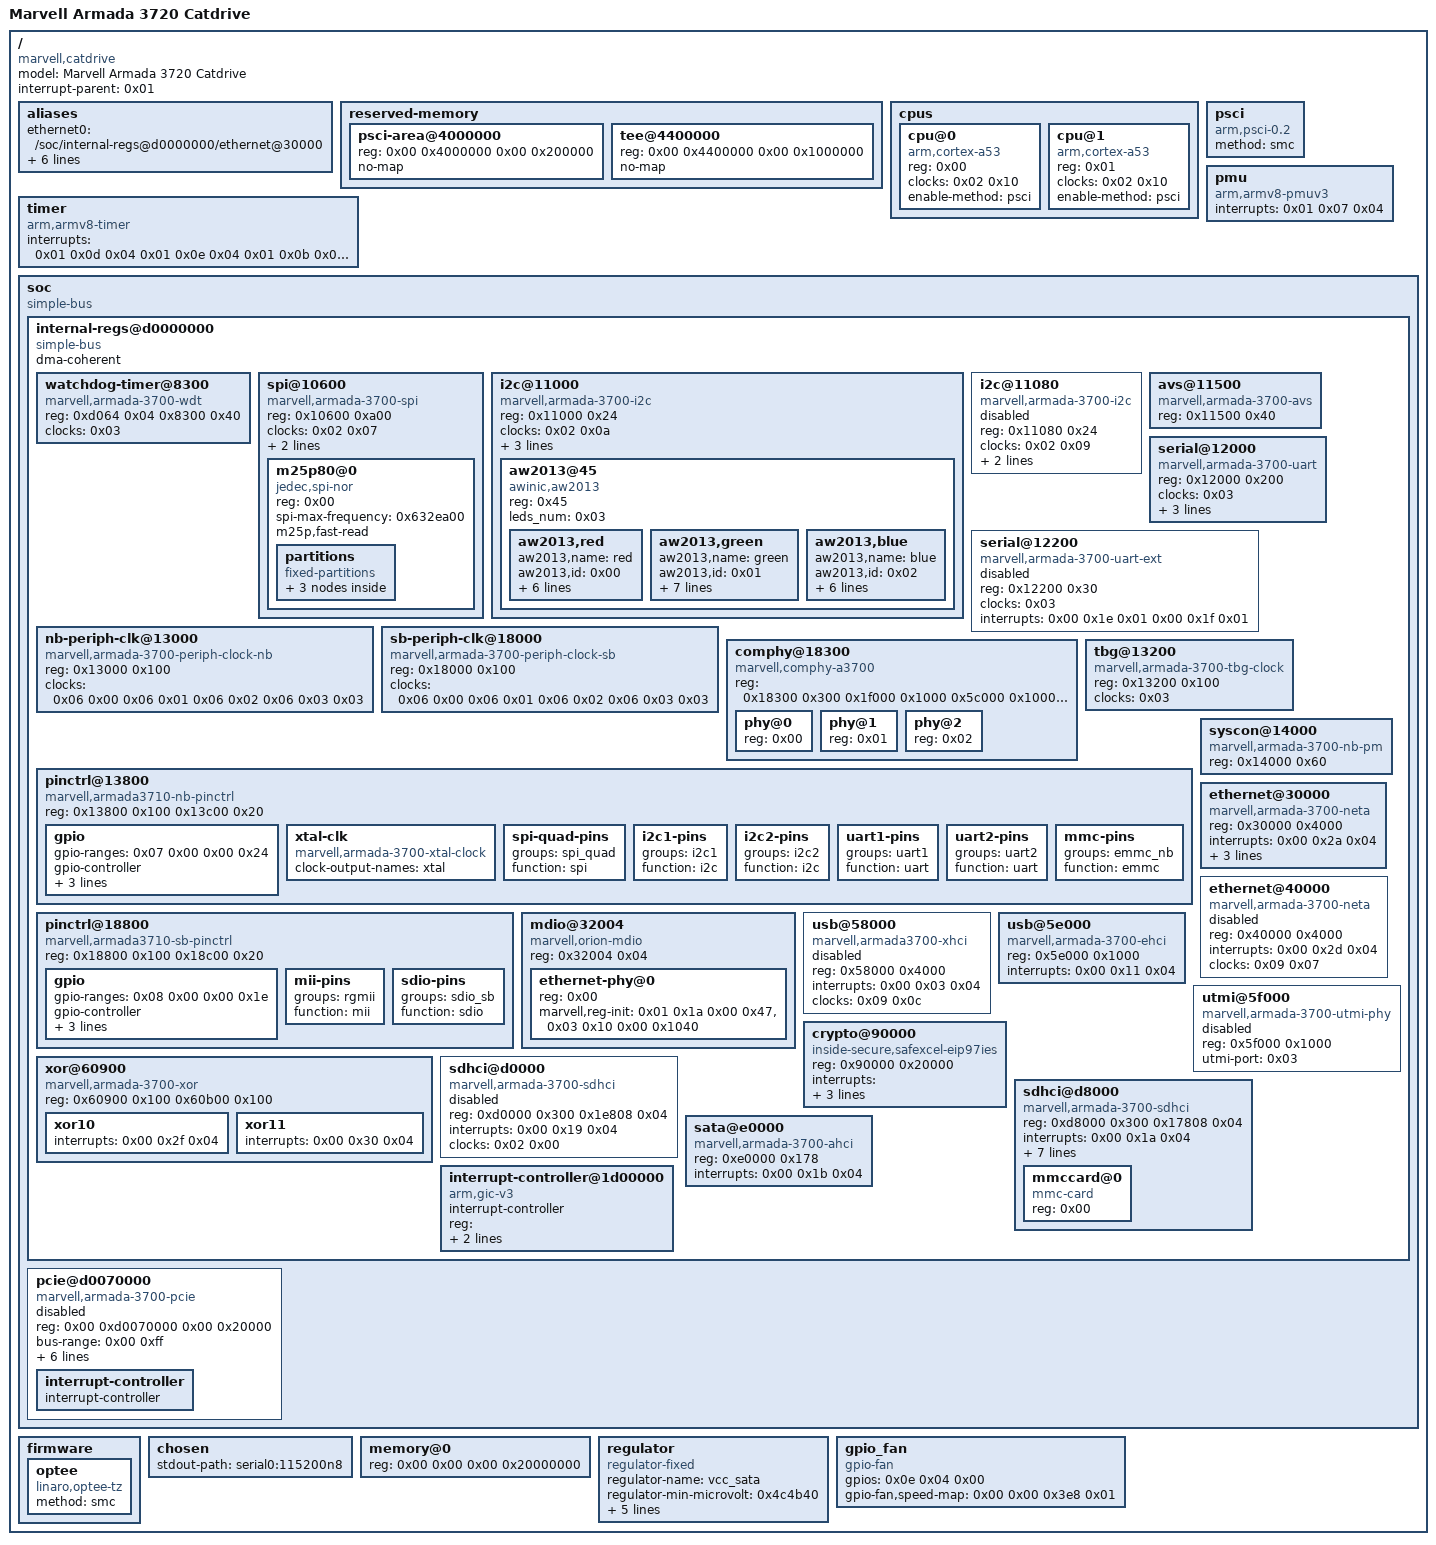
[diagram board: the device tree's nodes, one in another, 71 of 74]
/dts-v1/;

/ {
	model = "Marvell Armada 3720 Catdrive";
	compatible = "marvell,catdrive\0marvell,armada3720\0marvell,armada3710";
	interrupt-parent = <0x01>;
	#address-cells = <0x02>;
	#size-cells = <0x02>;

	aliases {
		ethernet0 = "/soc/internal-regs@d0000000/ethernet@30000";
		ethernet1 = "/soc/internal-regs@d0000000/ethernet@40000";
		serial0 = "/soc/internal-regs@d0000000/serial@12000";
		serial1 = "/soc/internal-regs@d0000000/serial@12200";
	};

	reserved-memory {
		#address-cells = <0x02>;
		#size-cells = <0x02>;
		ranges;

		psci-area@4000000 {
			reg = <0x00 0x4000000 0x00 0x200000>;
			no-map;
		};

		tee@4400000 {
			reg = <0x00 0x4400000 0x00 0x1000000>;
			no-map;
		};
	};

	cpus {
		#address-cells = <0x01>;
		#size-cells = <0x00>;

		cpu@0 {
			device_type = "cpu";
			compatible = "arm,cortex-a53\0arm,armv8";
			reg = <0x00>;
			clocks = <0x02 0x10>;
			enable-method = "psci";
		};

		cpu@1 {
			device_type = "cpu";
			compatible = "arm,cortex-a53\0arm,armv8";
			reg = <0x01>;
			clocks = <0x02 0x10>;
			enable-method = "psci";
		};
	};

	psci {
		compatible = "arm,psci-0.2";
		method = "smc";
	};

	timer {
		compatible = "arm,armv8-timer";
		interrupts = <0x01 0x0d 0x04 0x01 0x0e 0x04 0x01 0x0b 0x04 0x01 0x0a 0x04>;
	};

	pmu {
		compatible = "arm,armv8-pmuv3";
		interrupts = <0x01 0x07 0x04>;
	};

	soc {
		compatible = "simple-bus";
		#address-cells = <0x02>;
		#size-cells = <0x02>;
		ranges;

		internal-regs@d0000000 {
			#address-cells = <0x01>;
			#size-cells = <0x01>;
			compatible = "simple-bus";
			ranges = <0x00 0x00 0xd0000000 0x2000000>;
			dma-coherent;

			watchdog-timer@8300 {
				compatible = "marvell,armada-3700-wdt";
				reg = <0xd064 0x04 0x8300 0x40>;
				clocks = <0x03>;
			};

			spi@10600 {
				compatible = "marvell,armada-3700-spi";
				#address-cells = <0x01>;
				#size-cells = <0x00>;
				reg = <0x10600 0xa00>;
				clocks = <0x02 0x07>;
				interrupts = <0x00 0x00 0x04>;
				num-cs = <0x04>;
				status = "okay";

				m25p80@0 {
					reg = <0x00>;
					compatible = "jedec,spi-nor";
					spi-max-frequency = <0x632ea00>;
					m25p,fast-read;
					status = "okay";

					partitions {
						compatible = "fixed-partitions";
						#address-cells = <0x01>;
						#size-cells = <0x01>;

						partition@0 {
							label = "uboot";
							reg = <0x00 0x1f0000>;
						};

						partition@1f0000 {
							label = "ubootenv";
							reg = <0x1f0000 0x10000>;
						};

						partition@200000 {
							label = "reserve";
							reg = <0x200000 0x600000>;
						};
					};
				};
			};

			i2c@11000 {
				compatible = "marvell,armada-3700-i2c";
				reg = <0x11000 0x24>;
				#address-cells = <0x01>;
				#size-cells = <0x00>;
				clocks = <0x02 0x0a>;
				interrupts = <0x00 0x01 0x04>;
				mrvl,i2c-fast-mode;
				status = "okay";
				pinctrl-names = "default";
				pinctrl-0 = <0x04>;

				aw2013@45 {
					compatible = "awinic,aw2013";
					reg = <0x45>;
					leds_num = <0x03>;

					aw2013,red {
						aw2013,name = "red";
						aw2013,id = <0x00>;
						aw2013,max-brightness = <0xff>;
						aw2013,max-current = <0x03>;
						aw2013,rise-time-ms = <0x02>;
						aw2013,hold-time-ms = <0x01>;
						aw2013,fall-time-ms = <0x02>;
						aw2013,off-time-ms = <0x01>;
					};

					aw2013,green {
						aw2013,name = "green";
						aw2013,id = <0x01>;
						aw2013,max-brightness = <0xff>;
						aw2013,max-current = <0x03>;
						aw2013,rise-time-ms = <0x02>;
						aw2013,hold-time-ms = <0x01>;
						aw2013,fall-time-ms = <0x02>;
						aw2013,off-time-ms = <0x01>;
						default-state = "on";
					};

					aw2013,blue {
						aw2013,name = "blue";
						aw2013,id = <0x02>;
						aw2013,max-brightness = <0xff>;
						aw2013,max-current = <0x03>;
						aw2013,rise-time-ms = <0x02>;
						aw2013,hold-time-ms = <0x01>;
						aw2013,fall-time-ms = <0x02>;
						aw2013,off-time-ms = <0x01>;
					};
				};
			};

			i2c@11080 {
				compatible = "marvell,armada-3700-i2c";
				reg = <0x11080 0x24>;
				#address-cells = <0x01>;
				#size-cells = <0x00>;
				clocks = <0x02 0x09>;
				interrupts = <0x00 0x02 0x04>;
				mrvl,i2c-fast-mode;
				status = "disabled";
			};

			avs@11500 {
				compatible = "marvell,armada-3700-avs\0syscon";
				reg = <0x11500 0x40>;
			};

			serial@12000 {
				compatible = "marvell,armada-3700-uart";
				reg = <0x12000 0x200>;
				clocks = <0x03>;
				interrupts = <0x00 0x0b 0x04 0x00 0x0c 0x04 0x00 0x0d 0x04>;
				interrupt-names = "uart-sum\0uart-tx\0uart-rx";
				status = "okay";
				pinctrl-names = "default";
				pinctrl-0 = <0x05>;
			};

			serial@12200 {
				compatible = "marvell,armada-3700-uart-ext";
				reg = <0x12200 0x30>;
				clocks = <0x03>;
				interrupts = <0x00 0x1e 0x01 0x00 0x1f 0x01>;
				interrupt-names = "uart-tx\0uart-rx";
				status = "disabled";
			};

			nb-periph-clk@13000 {
				compatible = "marvell,armada-3700-periph-clock-nb";
				reg = <0x13000 0x100>;
				clocks = <0x06 0x00 0x06 0x01 0x06 0x02 0x06 0x03 0x03>;
				#clock-cells = <0x01>;
				linux,phandle = <0x02>;
				phandle = <0x02>;
			};

			sb-periph-clk@18000 {
				compatible = "marvell,armada-3700-periph-clock-sb";
				reg = <0x18000 0x100>;
				clocks = <0x06 0x00 0x06 0x01 0x06 0x02 0x06 0x03 0x03>;
				#clock-cells = <0x01>;
				linux,phandle = <0x09>;
				phandle = <0x09>;
			};

			comphy@18300 {
				compatible = "marvell,comphy-a3700";
				reg = <0x18300 0x300 0x1f000 0x1000 0x5c000 0x1000 0xe0178 0x08>;
				reg-names = "comphy\0serdes\0usb3_gbe1_phy\0indirect_ahci";
				#address-cells = <0x01>;
				#size-cells = <0x00>;

				phy@0 {
					reg = <0x00>;
					#phy-cells = <0x01>;
				};

				phy@1 {
					reg = <0x01>;
					#phy-cells = <0x01>;
				};

				phy@2 {
					reg = <0x02>;
					#phy-cells = <0x01>;
				};
			};

			tbg@13200 {
				compatible = "marvell,armada-3700-tbg-clock";
				reg = <0x13200 0x100>;
				clocks = <0x03>;
				#clock-cells = <0x01>;
				linux,phandle = <0x06>;
				phandle = <0x06>;
			};

			pinctrl@13800 {
				compatible = "marvell,armada3710-nb-pinctrl\0syscon\0simple-mfd";
				reg = <0x13800 0x100 0x13c00 0x20>;
				linux,phandle = <0x07>;
				phandle = <0x07>;

				gpio {
					#gpio-cells = <0x02>;
					gpio-ranges = <0x07 0x00 0x00 0x24>;
					gpio-controller;
					interrupt-controller;
					#interrupt-cells = <0x02>;
					interrupts = <0x00 0x33 0x04 0x00 0x34 0x04 0x00 0x35 0x04 0x00 0x36 0x04 0x00 0x37 0x04 0x00 0x38 0x04 0x00 0x39 0x04 0x00 0x3a 0x04 0x00 0x98 0x04 0x00 0x99 0x04 0x00 0x9a 0x04 0x00 0x9b 0x04>;
				};

				xtal-clk {
					compatible = "marvell,armada-3700-xtal-clock";
					clock-output-names = "xtal";
					#clock-cells = <0x00>;
					linux,phandle = <0x03>;
					phandle = <0x03>;
				};

				spi-quad-pins {
					groups = "spi_quad";
					function = "spi";
				};

				i2c1-pins {
					groups = "i2c1";
					function = "i2c";
					linux,phandle = <0x04>;
					phandle = <0x04>;
				};

				i2c2-pins {
					groups = "i2c2";
					function = "i2c";
				};

				uart1-pins {
					groups = "uart1";
					function = "uart";
					linux,phandle = <0x05>;
					phandle = <0x05>;
				};

				uart2-pins {
					groups = "uart2";
					function = "uart";
				};

				mmc-pins {
					groups = "emmc_nb";
					function = "emmc";
					linux,phandle = <0x0b>;
					phandle = <0x0b>;
				};
			};

			syscon@14000 {
				compatible = "marvell,armada-3700-nb-pm\0syscon";
				reg = <0x14000 0x60>;
			};

			pinctrl@18800 {
				compatible = "marvell,armada3710-sb-pinctrl\0syscon\0simple-mfd";
				reg = <0x18800 0x100 0x18c00 0x20>;
				linux,phandle = <0x08>;
				phandle = <0x08>;

				gpio {
					#gpio-cells = <0x02>;
					gpio-ranges = <0x08 0x00 0x00 0x1e>;
					gpio-controller;
					interrupt-controller;
					#interrupt-cells = <0x02>;
					interrupts = <0x00 0xa0 0x04 0x00 0x9f 0x04 0x00 0x9e 0x04 0x00 0x9d 0x04 0x00 0x9c 0x04>;
					linux,phandle = <0x0e>;
					phandle = <0x0e>;
				};

				mii-pins {
					groups = "rgmii";
					function = "mii";
				};

				sdio-pins {
					groups = "sdio_sb";
					function = "sdio";
				};
			};

			ethernet@30000 {
				compatible = "marvell,armada-3700-neta";
				reg = <0x30000 0x4000>;
				interrupts = <0x00 0x2a 0x04>;
				clocks = <0x09 0x08>;
				status = "okay";
				phy-mode = "sgmii";
				phy = <0x0a>;
			};

			mdio@32004 {
				#address-cells = <0x01>;
				#size-cells = <0x00>;
				compatible = "marvell,orion-mdio";
				reg = <0x32004 0x04>;
				status = "okay";

				ethernet-phy@0 {
					reg = <0x00>;
					marvell,reg-init = <0x01 0x1a 0x00 0x47>, <0x03 0x10 0x00 0x1040>;
					linux,phandle = <0x0a>;
					phandle = <0x0a>;
				};
			};

			ethernet@40000 {
				compatible = "marvell,armada-3700-neta";
				reg = <0x40000 0x4000>;
				interrupts = <0x00 0x2d 0x04>;
				clocks = <0x09 0x07>;
				status = "disabled";
			};

			usb@58000 {
				compatible = "marvell,armada3700-xhci\0generic-xhci";
				reg = <0x58000 0x4000>;
				interrupts = <0x00 0x03 0x04>;
				clocks = <0x09 0x0c>;
				status = "disabled";
			};

			usb@5e000 {
				compatible = "marvell,armada-3700-ehci";
				reg = <0x5e000 0x1000>;
				interrupts = <0x00 0x11 0x04>;
				status = "okay";
			};

			utmi@5f000 {
				compatible = "marvell,armada-3700-utmi-phy";
				reg = <0x5f000 0x1000>;
				utmi-port = <0x03>;
				#phy-cells = <0x00>;
				status = "disabled";
			};

			xor@60900 {
				compatible = "marvell,armada-3700-xor";
				reg = <0x60900 0x100 0x60b00 0x100>;

				xor10 {
					interrupts = <0x00 0x2f 0x04>;
				};

				xor11 {
					interrupts = <0x00 0x30 0x04>;
				};
			};

			crypto@90000 {
				compatible = "inside-secure,safexcel-eip97ies";
				reg = <0x90000 0x20000>;
				interrupts = <0x00 0x13 0x04 0x00 0x14 0x04 0x00 0x15 0x04 0x00 0x16 0x04 0x00 0x17 0x04 0x00 0x18 0x04>;
				interrupt-names = "mem\0ring0\0ring1\0ring2\0ring3\0eip";
				clocks = <0x02 0x0f>;
				cell-index = <0x00>;
			};

			sdhci@d0000 {
				compatible = "marvell,armada-3700-sdhci\0marvell,sdhci-xenon";
				reg = <0xd0000 0x300 0x1e808 0x04>;
				interrupts = <0x00 0x19 0x04>;
				clocks = <0x02 0x00>;
				clock-names = "core";
				status = "disabled";
			};

			sdhci@d8000 {
				compatible = "marvell,armada-3700-sdhci\0marvell,sdhci-xenon";
				reg = <0xd8000 0x300 0x17808 0x04>;
				interrupts = <0x00 0x1a 0x04>;
				clocks = <0x02 0x00>;
				clock-names = "core";
				status = "okay";
				non-removable;
				bus-width = <0x08>;
				mmc-ddr-1_8v;
				mmc-hs200-1_8v;
				marvell,pad-type = "fixed-1-8v";
				pinctrl-names = "default";
				pinctrl-0 = <0x0b>;
				#address-cells = <0x01>;
				#size-cells = <0x00>;

				mmccard@0 {
					compatible = "mmc-card";
					reg = <0x00>;
				};
			};

			sata@e0000 {
				compatible = "marvell,armada-3700-ahci";
				reg = <0xe0000 0x178>;
				interrupts = <0x00 0x1b 0x04>;
				status = "okay";
			};

			interrupt-controller@1d00000 {
				compatible = "arm,gic-v3";
				#interrupt-cells = <0x03>;
				interrupt-controller;
				reg = <0x1d00000 0x10000 0x1d40000 0x40000 0x1d80000 0x2000 0x1d90000 0x2000 0x1da0000 0x20000>;
				interrupts = <0x01 0x09 0x04>;
				linux,phandle = <0x01>;
				phandle = <0x01>;
			};
		};

		pcie@d0070000 {
			compatible = "marvell,armada-3700-pcie";
			device_type = "pci";
			status = "disabled";
			reg = <0x00 0xd0070000 0x00 0x20000>;
			#address-cells = <0x03>;
			#size-cells = <0x02>;
			bus-range = <0x00 0xff>;
			interrupts = <0x00 0x1d 0x04>;
			#interrupt-cells = <0x01>;
			msi-parent = <0x0c>;
			msi-controller;
			ranges = <0x82000000 0x00 0xe8000000 0x00 0xe8000000 0x00 0x1000000 0x81000000 0x00 0xe9000000 0x00 0xe9000000 0x00 0x10000>;
			interrupt-map-mask = <0x00 0x00 0x00 0x07>;
			interrupt-map = <0x00 0x00 0x00 0x01 0x0d 0x00 0x00 0x00 0x00 0x02 0x0d 0x01 0x00 0x00 0x00 0x03 0x0d 0x02 0x00 0x00 0x00 0x04 0x0d 0x03>;
			linux,phandle = <0x0c>;
			phandle = <0x0c>;

			interrupt-controller {
				interrupt-controller;
				#interrupt-cells = <0x01>;
				linux,phandle = <0x0d>;
				phandle = <0x0d>;
			};
		};
	};

	firmware {

		optee {
			compatible = "linaro,optee-tz";
			method = "smc";
			status = "okay";
		};
	};

	chosen {
		stdout-path = "serial0:115200n8";
	};

	memory@0 {
		device_type = "memory";
		reg = <0x00 0x00 0x00 0x20000000>;
	};

	regulator {
		compatible = "regulator-fixed";
		regulator-name = "vcc_sata";
		regulator-min-microvolt = <0x4c4b40>;
		regulator-max-microvolt = <0x4c4b40>;
		regulator-boot-on;
		regulator-always-on;
		enable-active-high;
		gpio = <0x0e 0x00 0x00>;
	};

	gpio_fan {
		compatible = "gpio-fan";
		gpios = <0x0e 0x04 0x00>;
		gpio-fan,speed-map = <0x00 0x00 0x3e8 0x01>;
	};
};
